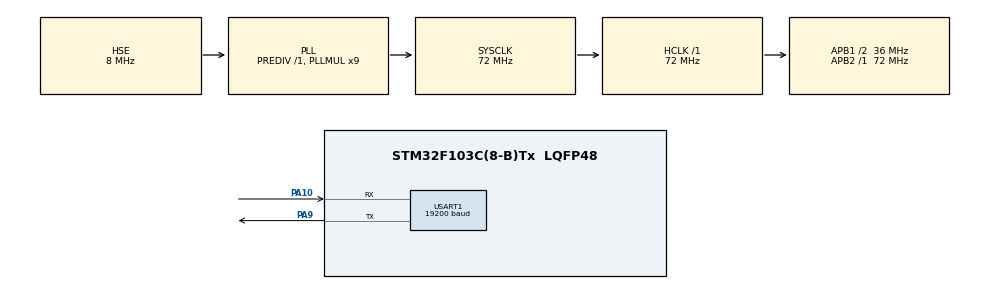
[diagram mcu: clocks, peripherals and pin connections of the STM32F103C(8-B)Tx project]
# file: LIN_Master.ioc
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Mcu.Family=STM32F1
Mcu.Name=STM32F103C(8-B)Tx
Mcu.Package=LQFP48
NVIC.PriorityGroup=NVIC_PRIORITYGROUP_4
PA10.Mode=LIN
PA10.Signal=USART1_RX
PA13.Mode=Serial_Wire
PA13.Signal=SYS_JTMS-SWDIO
PA14.Mode=Serial_Wire
PA14.Signal=SYS_JTCK-SWCLK
PA9.Mode=LIN
PA9.Signal=USART1_TX
PD0-OSC_IN.Mode=HSE-External-Oscillator
PD0-OSC_IN.Signal=RCC_OSC_IN
PD1-OSC_OUT.Mode=HSE-External-Oscillator
PD1-OSC_OUT.Signal=RCC_OSC_OUT
ProjectManager.HeapSize=0x200
ProjectManager.StackSize=0x400
ProjectManager.TargetToolchain=STM32CubeIDE
RCC.AHBFreq_Value=72000000
RCC.APB1CLKDivider=RCC_HCLK_DIV2
RCC.APB1Freq_Value=36000000
RCC.APB1TimFreq_Value=72000000
RCC.APB2Freq_Value=72000000
RCC.APB2TimFreq_Value=72000000
RCC.HCLKFreq_Value=72000000
RCC.PLLMUL=RCC_PLL_MUL9
RCC.PLLSourceVirtual=RCC_PLLSOURCE_HSE
RCC.SYSCLKFreq_VALUE=72000000
RCC.SYSCLKSource=RCC_SYSCLKSOURCE_PLLCLK
RCC.USBFreq_Value=72000000
USART1.BaudRate=19200
USART1.BreakDetectLength=UART_LINBREAKDETECTLENGTH_11B
USART1.VirtualMode=VM_ASYNC
board=custom

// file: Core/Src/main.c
/* USER CODE BEGIN Header */
/**
  ******************************************************************************
  * @file           : main.c
  * @brief          : Main program body
  ******************************************************************************
  * @attention
  *
  * Copyright (c) 2026 STMicroelectronics.
  * All rights reserved.
  *
  * This software is licensed under terms that can be found in the LICENSE file
  * in the root directory of this software component.
  * If no LICENSE file comes with this software, it is provided AS-IS.
  *
  ******************************************************************************
  */
/* USER CODE END Header */
#include "main.h"

/* USER CODE BEGIN Includes */
#include <string.h>
/* USER CODE END Includes */

UART_HandleTypeDef huart1;

/* USER CODE BEGIN PV */
static uint8_t lin_rx_buf[3];   /* 2 data bytes + checksum */
static uint16_t adc_raw = 0;
static float voltage = 0.0f;
/* USER CODE END PV */

void SystemClock_Config(void);
static void MX_GPIO_Init(void);
static void MX_USART1_UART_Init(void);
/* USER CODE BEGIN PFP */
static uint8_t lin_checksum(const uint8_t *data, uint8_t len);
static void lin_send_break_sync(void);
static HAL_StatusTypeDef lin_master_request(uint8_t pid, uint8_t *buf, uint8_t len);
/* USER CODE END PFP */

/* USER CODE BEGIN 0 */
/* Classic LIN checksum: inverted carry-around sum of data bytes */
static uint8_t lin_checksum(const uint8_t *data, uint8_t len)
{
  uint16_t sum = 0;

  for (uint8_t i = 0; i < len; i++)
  {
    sum += data[i];
    if (sum > 0xFF)
    {
      sum -= 0xFF;
    }
  }

  return (uint8_t)(~sum & 0xFF);
}

/* Send LIN break (~13 dominant bits) then sync byte 0x55 */
static void lin_send_break_sync(void)
{
  /* Lower baud to ~8000 bps -> one 0x00 byte covers >13 bit-times */
  huart1.Init.BaudRate = 8000;
  HAL_UART_Init(&huart1);

  uint8_t brk = 0x00;
  HAL_UART_Transmit(&huart1, &brk, 1, HAL_MAX_DELAY);

  /* Restore normal speed, then send sync byte */
  huart1.Init.BaudRate = 19200;
  HAL_UART_Init(&huart1);

  uint8_t sync = 0x55;
  HAL_UART_Transmit(&huart1, &sync, 1, HAL_MAX_DELAY);
}

/* Transmit LIN header then receive response bytes */
static HAL_StatusTypeDef lin_master_request(uint8_t pid, uint8_t *buf, uint8_t len)
{
  lin_send_break_sync();
  HAL_UART_Transmit(&huart1, &pid, 1, HAL_MAX_DELAY);
  return HAL_UART_Receive(&huart1, buf, len, 100);
}
/* USER CODE END 0 */

int main(void)
{

  /* MCU Configuration--------------------------------------------------------*/

  /* Reset of all peripherals, Initializes the Flash interface and the Systick. */
  HAL_Init();

  /* Configure the system clock */
  SystemClock_Config();

  /* Initialize all configured peripherals */
  MX_GPIO_Init();
  MX_USART1_UART_Init();

  /* Infinite loop */
  /* USER CODE BEGIN WHILE */
while (1)
  {
    /* Request frame ID 0x01: 2 data bytes + 1 checksum */
    if (lin_master_request(0x01, lin_rx_buf, 3) == HAL_OK)
    {
      uint8_t crc = lin_checksum(lin_rx_buf, 2);

      if (crc == lin_rx_buf[2])
      {
        adc_raw = ((uint16_t)lin_rx_buf[0] << 8) | lin_rx_buf[1];
        voltage = ((float)adc_raw / 4095.0f) * 3.3f;
      }
    }

    HAL_Delay(500);   /* Set breakpoint here and watch adc_raw + voltage */
/* USER CODE END WHILE */

  }
}

void SystemClock_Config(void)
{
  RCC_OscInitTypeDef RCC_OscInitStruct = {0};
  RCC_ClkInitTypeDef RCC_ClkInitStruct = {0};

  /** Initializes the RCC Oscillators according to the specified parameters
  * in the RCC_OscInitTypeDef structure.
  */
  RCC_OscInitStruct.OscillatorType = RCC_OSCILLATORTYPE_HSE;
  RCC_OscInitStruct.HSEState = RCC_HSE_ON;
  RCC_OscInitStruct.HSEPredivValue = RCC_HSE_PREDIV_DIV1;
  RCC_OscInitStruct.HSIState = RCC_HSI_ON;
  RCC_OscInitStruct.PLL.PLLState = RCC_PLL_ON;
  RCC_OscInitStruct.PLL.PLLSource = RCC_PLLSOURCE_HSE;
  RCC_OscInitStruct.PLL.PLLMUL = RCC_PLL_MUL9;
  if (HAL_RCC_OscConfig(&RCC_OscInitStruct) != HAL_OK)
  {
    Error_Handler();
  }

  /** Initializes the CPU, AHB and APB buses clocks
  */
  RCC_ClkInitStruct.ClockType = RCC_CLOCKTYPE_HCLK|RCC_CLOCKTYPE_SYSCLK
                              |RCC_CLOCKTYPE_PCLK1|RCC_CLOCKTYPE_PCLK2;
  RCC_ClkInitStruct.SYSCLKSource = RCC_SYSCLKSOURCE_PLLCLK;
  RCC_ClkInitStruct.AHBCLKDivider = RCC_SYSCLK_DIV1;
  RCC_ClkInitStruct.APB1CLKDivider = RCC_HCLK_DIV2;
  RCC_ClkInitStruct.APB2CLKDivider = RCC_HCLK_DIV1;

  if (HAL_RCC_ClockConfig(&RCC_ClkInitStruct, FLASH_LATENCY_2) != HAL_OK)
  {
    Error_Handler();
  }
}

static void MX_USART1_UART_Init(void)
{

  huart1.Instance = USART1;
  huart1.Init.BaudRate = 19200;
  huart1.Init.WordLength = UART_WORDLENGTH_8B;
  huart1.Init.StopBits = UART_STOPBITS_1;
  huart1.Init.Parity = UART_PARITY_NONE;
  huart1.Init.Mode = UART_MODE_TX_RX;
  huart1.Init.HwFlowCtl = UART_HWCONTROL_NONE;
  if (HAL_LIN_Init(&huart1, UART_LINBREAKDETECTLENGTH_11B) != HAL_OK)
  {
    Error_Handler();
  }

}

static void MX_GPIO_Init(void)
{

  /* GPIO Ports Clock Enable */
  __HAL_RCC_GPIOD_CLK_ENABLE();
  __HAL_RCC_GPIOA_CLK_ENABLE();

}

void Error_Handler(void)
{
  __disable_irq();
  while (1)
  {
  }
}
